# GD32C11x register map
File version: 1.0
CPU: CM4 r2p1, little endian, no MPU, FPU, 4 interrupt priority bits
Registers are 32-bit, read-write, reset 0x0 unless marked. A register's access mark holds for its fields unless they carry their own. Offsets are from the block's base; [hi:lo] are bit positions.

## SPI0 — Serial peripheral interface
Base 0x40013000
Same registers: SPI1 0x40003800, SPI2 0x40003C00
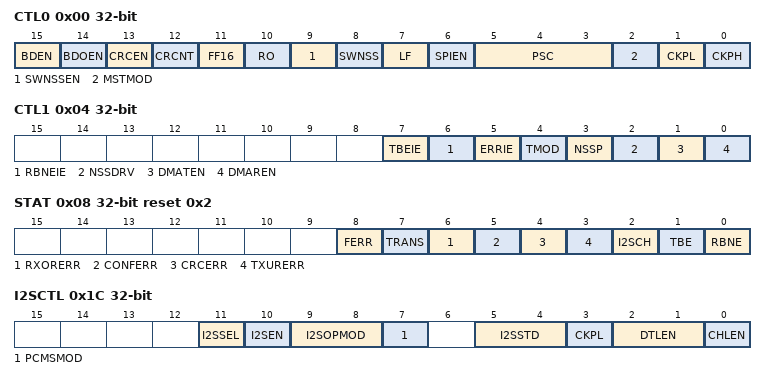
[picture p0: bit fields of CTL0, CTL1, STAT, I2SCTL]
0x00 CTL0 — control register 0
  [15] BDEN — Bidirectional enable
  [14] BDOEN — Bidirectional Transmit output enable
  [13] CRCEN — CRC Calculation Enable
  [12] CRCNT — CRC Next Transfer
  [11] FF16 — Data frame format
  [10] RO — Receive only
  [9] SWNSSEN — NSS Software Mode Selection
  [8] SWNSS — NSS Pin Selection In NSS Software Mode
  [7] LF — LSB First Mode
  [6] SPIEN — SPI enable
  [5:3] PSC — Master Clock Prescaler Selection
  [2] MSTMOD — Master Mode Enable
  [1] CKPL — Clock polarity Selection
  [0] CKPH — Clock Phase Selection
0x04 CTL1 — control register 1
  [7] TBEIE — Tx buffer empty interrupt enable
  [6] RBNEIE — RX buffer not empty interrupt enable
  [5] ERRIE — Error interrupt enable
  [4] TMOD — SPI TI Mode Enable
  [3] NSSP — SPI NSS pulse mode Enable
  [2] NSSDRV — Drive NSS Output
  [1] DMATEN — Transmit Buffer DMA Enable
  [0] DMAREN — Rx buffer DMA enable
0x08 STAT access per field reset 0x2 — status register
  [8] FERR rw — Format Error
  [7] TRANS ro — Transmitting On-going Bit
  [6] RXORERR ro — Reception Overrun Error Bit
  [5] CONFERR ro — SPI Configuration error
  [4] CRCERR rw — SPI CRC Error Bit
  [3] TXURERR ro — Transmission underrun error bit
  [2] I2SCH ro — I2S channel side
  [1] TBE ro — Transmit Buffer Empty
  [0] RBNE ro — Receive Buffer Not Empty
0x0C DATA
  [15:0] SPI_DATA — Data transfer register
0x10 CRCPOLY reset 0x7 — CRC polynomial register
  [15:0] CRCPOLY
0x14 RCRC ro — RX CRC register
  [15:0] RCRC
0x18 TCRC ro — TX CRC register
  [15:0] TCRC — Tx CRC register
0x1C I2SCTL — I2S control register
  [11] I2SSEL — I2S mode selection
  [10] I2SEN — I2S Enable
  [9:8] I2SOPMOD — I2S operation mode
  [7] PCMSMOD — PCM frame synchronization mode
  [5:4] I2SSTD — I2S standard selection
  [3] CKPL — Idle state clock polarity
  [2:1] DTLEN — Data length
  [0] CHLEN — Channel length (number of bits per audio channel)
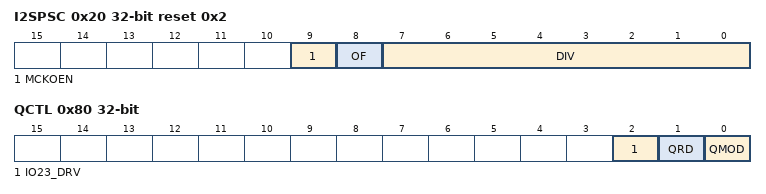
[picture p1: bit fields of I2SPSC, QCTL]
0x20 I2SPSC reset 0x2 — I2S prescaler register
  [9] MCKOEN — I2S_MCK output enable
  [8] OF — Odd factor for the prescaler
  [7:0] DIV — Dividing factor for the prescaler
0x80 QCTL — Quad-SPI mode control register
  [2] IO23_DRV — Drive IO2 and IO3 enable
  [1] QRD — Quad-SPI mode read select
  [0] QMOD — Quad-SPI mode enable

## TIMER5 — Basic-timers
Base 0x40001000
Same registers: TIMER6 0x40001400
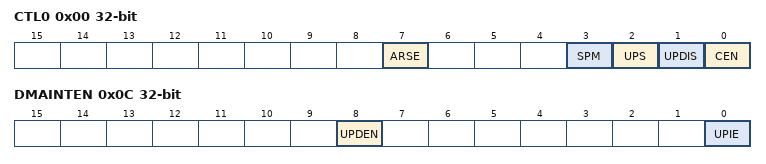
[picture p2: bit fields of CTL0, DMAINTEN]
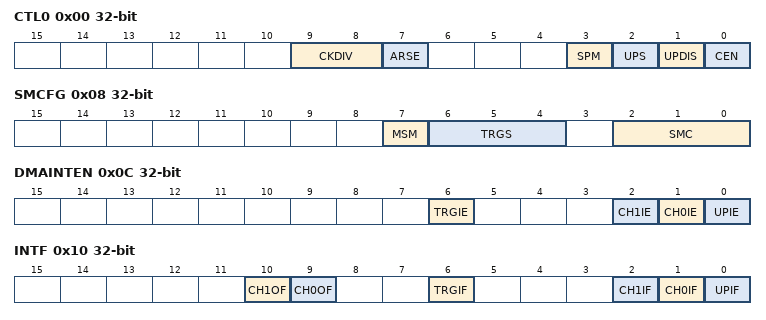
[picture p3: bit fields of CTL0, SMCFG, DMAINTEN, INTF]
0x00 CTL0 — control register 0
  [7] ARSE — Auto-reload shadow enable
  [3] SPM — Single pulse mode
  [2] UPS — Update source
  [1] UPDIS — Update disable
  [0] CEN — Counter enable
0x04 CTL1 — control register 1
  [6:4] MMC — Master mode control
0x0C DMAINTEN — DMA/Interrupt enable register
  [8] UPDEN — Update DMA request enable
  [0] UPIE — Update interrupt enable
0x10 INTF — Interrupt flag register
  [0] UPIF — Update interrupt flag
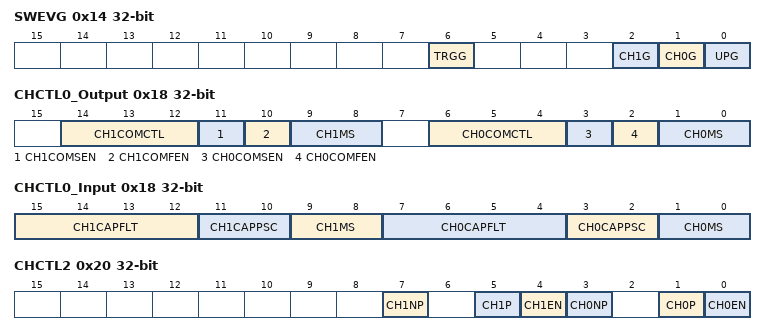
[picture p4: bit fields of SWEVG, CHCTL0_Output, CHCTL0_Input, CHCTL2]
0x14 SWEVG wo — event generation register
  [0] UPG — Update generation
0x24 CNT — Counter register
  [15:0] CNT — Low counter value
0x28 PSC — Prescaler register
  [15:0] PSC — Prescaler value of the counter clock
0x2C CAR — Counter auto reload register
  [15:0] CARL — Counter auto reload value

## TIMER8 — General-purpose-timers
Base 0x40014C00
Same registers: TIMER11 0x40001800
0x00 CTL0 — control register 0
  [9:8] CKDIV — Clock division
  [7] ARSE — Auto-reload shadow enable
  [3] SPM — Single pulse mode
  [2] UPS — Update source
  [1] UPDIS — Update disable
  [0] CEN — Counter enable
0x08 SMCFG — slave mode configuration register
  [7] MSM — Master-slave mode
  [6:4] TRGS — Trigger selection
  [2:0] SMC — Slave mode control
0x0C DMAINTEN — DMA and interrupt enable register
  [6] TRGIE — Trigger interrupt enable
  [2] CH1IE — Channel 1 capture/compare interrupt enable
  [1] CH0IE — Channel 0 capture/compare interrupt enable
  [0] UPIE — Update interrupt enable
0x10 INTF — interrupt flag register
  [10] CH1OF — Channel 1 over capture flag
  [9] CH0OF — Channel 0 over capture flag
  [6] TRGIF — Trigger interrupt flag
  [2] CH1IF — Channel 1 capture/compare interrupt flag
  [1] CH0IF — Channel 0 capture/compare interrupt flag
  [0] UPIF — Update interrupt flag
0x14 SWEVG wo — event generation register
  [6] TRGG — Trigger event generation
  [2] CH1G — Channel 1 capture or compare event generation
  [1] CH0G — Channel 0 capture or compare event generation
  [0] UPG — Update generation
0x18 CHCTL0_Output — Channel control register 0 (output mode)
  [14:12] CH1COMCTL — Channel 1 compare output control
  [11] CH1COMSEN — Channel 1 output compare shadow enable
  [10] CH1COMFEN — Channel 1 output compare fast enable
  [9:8] CH1MS — Channel 1 mode selection
  [6:4] CH0COMCTL — Channel 0 compare output control
  [3] CH0COMSEN — Channel 0 compare output shadow enable
  [2] CH0COMFEN — Channel 0 output compare fast enable
  [1:0] CH0MS — Channel 0 I/O mode selection
0x18 CHCTL0_Input (alternate view of CHCTL0_Output) — Channel control register 0 (input mode)
  [15:12] CH1CAPFLT — Channel 1 input capture filter control
  [11:10] CH1CAPPSC — Channel 1 input capture prescaler
  [9:8] CH1MS — Channel 1 mode selection
  [7:4] CH0CAPFLT — Channel 0 input capture filter control
  [3:2] CH0CAPPSC — Channel 0 input capture prescaler
  [1:0] CH0MS — Channel 0 mode selection
0x20 CHCTL2 — Channel control register 2
  [7] CH1NP — Channel 1 complementary output polarity
  [5] CH1P — Channel 1 capture/compare function polarity
  [4] CH1EN — Channel 1 capture/compare function enable
  [3] CH0NP — Channel 0 complementary output polarity
  [1] CH0P — Channel 0 capture/compare function polarity
  [0] CH0EN — Channel 0 capture/compare function enable
0x24 CNT — Counter register
  [15:0] CNT — current counter value
0x28 PSC — Prescaler register
  [15:0] PSC — Prescaler value of the counter clock
0x2C CAR — Counter auto reload register
  [15:0] CARL — Counter auto reload value
0x34 CH0CV — Channel 0 capture/compare value register
  [15:0] CH0VAL — Capture or compare value of channel0
0x38 CH1CV — Channel 1 capture/compare value register
  [15:0] CH1VAL — Capture or compare value of channel1
0xFC CFG — configuration register
  [1] CHVSEL — Write CHxVAL register selection
